# MKL05Z4 register map
Vendor: Freescale Semiconductor, Inc.; Series: Kinetis_L; File version: 1.6
CPU: CM0PLUS r0p0, little endian, no MPU, no FPU, VTOR, 2 interrupt priority bits
Registers are 32-bit, read-write, reset 0x0 unless marked. A register's access mark holds for its fields unless they carry their own. Offsets are from the block's base; [hi:lo] are bit positions; {n}, {i} and the like mark numbered series.

## NVIC — Nested Vectored Interrupt Controller
Base 0xE000E100
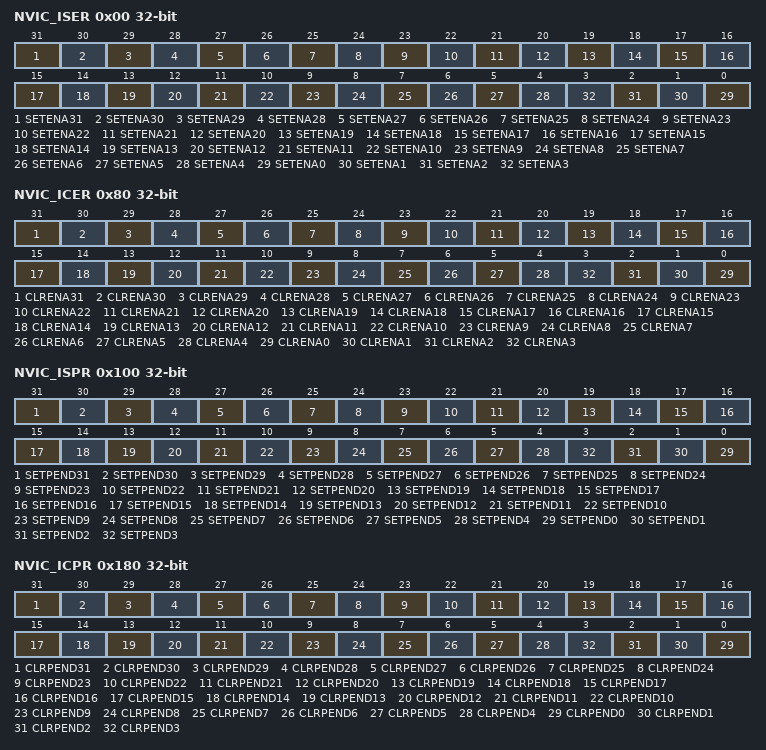
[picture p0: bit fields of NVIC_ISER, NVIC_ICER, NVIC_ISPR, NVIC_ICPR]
0x00 NVIC_ISER — Interrupt Set Enable Register
  [31] SETENA31
    0=write: no effect; read: PORTB Pin detect interrupt disabled; 1=write: enable PORTB Pin detect interrupt; read: PORTB Pin detect interrupt enabled
  [30] SETENA30
    0=write: no effect; read: PORTA Pin detect interrupt disabled; 1=write: enable PORTA Pin detect interrupt; read: PORTA Pin detect interrupt enabled
  [29] SETENA29
    0=write: no effect; read: Reserved iv 45 interrupt disabled; 1=write: enable Reserved iv 45 interrupt; read: Reserved iv 45 interrupt enabled
  [28] SETENA28
    0=write: no effect; read: Low-Power Timer interrupt disabled; 1=write: enable Low-Power Timer interrupt; read: Low-Power Timer interrupt enabled
  [27] SETENA27
    0=write: no effect; read: Multipurpose Clock Generator interrupt disabled; 1=write: enable Multipurpose Clock Generator interrupt; read: Multipurpose Clock Generator interrupt enabled
  [26] SETENA26
    0=write: no effect; read: Touch Sensing Input interrupt disabled; 1=write: enable Touch Sensing Input interrupt; read: Touch Sensing Input interrupt enabled
  [25] SETENA25
    0=write: no effect; read: Digital to Analog Converter interrupt disabled; 1=write: enable Digital to Analog Converter interrupt; read: Digital to Analog Converter interrupt enabled
  [24] SETENA24
    0=write: no effect; read: Reserved iv 40 interrupt disabled; 1=write: enable Reserved iv 40 interrupt; read: Reserved iv 40 interrupt enabled
  [23] SETENA23
    0=write: no effect; read: Reserved iv 39 interrupt disabled; 1=write: enable Reserved iv 39 interrupt; read: Reserved iv 39 interrupt enabled
  [22] SETENA22
    0=write: no effect; read: Periodic Interrupt Timer interrupt disabled; 1=write: enable Periodic Interrupt Timer interrupt; read: Periodic Interrupt Timer interrupt enabled
  [21] SETENA21
    0=write: no effect; read: RTC seconds interrupt disabled; 1=write: enable RTC seconds interrupt; read: RTC seconds interrupt enabled
  [20] SETENA20
    0=write: no effect; read: Real-time counter interrupt disabled; 1=write: enable Real-time counter interrupt; read: Real-time counter interrupt enabled
  [19] SETENA19
    0=write: no effect; read: Reserved iv 35 interrupt disabled; 1=write: enable Reserved iv 35 interrupt; read: Reserved iv 35 interrupt enabled
  [18] SETENA18
    0=write: no effect; read: Timer/PWM module 1 interrupt disabled; 1=write: enable Timer/PWM module 1 interrupt; read: Timer/PWM module 1 interrupt enabled
  [17] SETENA17
    0=write: no effect; read: Timer/PWM module 0 interrupt disabled; 1=write: enable Timer/PWM module 0 interrupt; read: Timer/PWM module 0 interrupt enabled
  [16] SETENA16
    0=write: no effect; read: Comparator 0 interrupt disabled; 1=write: enable Comparator 0 interrupt; read: Comparator 0 interrupt enabled
  [15] SETENA15
    0=write: no effect; read: Analog-to-Digital Converter 0 interrupt disabled; 1=write: enable Analog-to-Digital Converter 0 interrupt; read: Analog-to-Digital Converter 0 interrupt enabled
  [14] SETENA14
    0=write: no effect; read: Reserved iv 30 interrupt disabled; 1=write: enable Reserved iv 30 interrupt; read: Reserved iv 30 interrupt enabled
  [13] SETENA13
    0=write: no effect; read: Reserved iv 29 interrupt disabled; 1=write: enable Reserved iv 29 interrupt; read: Reserved iv 29 interrupt enabled
  [12] SETENA12
    0=write: no effect; read: UART0 status and error interrupt disabled; 1=write: enable UART0 status and error interrupt; read: UART0 status and error interrupt enabled
  [11] SETENA11
    0=write: no effect; read: Reserved iv 27 interrupt disabled; 1=write: enable Reserved iv 27 interrupt; read: Reserved iv 27 interrupt enabled
  [10] SETENA10
    0=write: no effect; read: Serial Peripheral Interface 0 interrupt disabled; 1=write: enable Serial Peripheral Interface 0 interrupt; read: Serial Peripheral Interface 0 interrupt enabled
  [9] SETENA9
    0=write: no effect; read: Reserved iv 25 interrupt disabled; 1=write: enable Reserved iv 25 interrupt; read: Reserved iv 25 interrupt enabled
  [8] SETENA8
    0=write: no effect; read: Inter-Integrated Circuit 0 interrupt disabled; 1=write: enable Inter-Integrated Circuit 0 interrupt; read: Inter-Integrated Circuit 0 interrupt enabled
  [7] SETENA7
    0=write: no effect; read: Low Leakage Wakeup interrupt disabled; 1=write: enable Low Leakage Wakeup interrupt; read: Low Leakage Wakeup interrupt enabled
  [6] SETENA6
    0=write: no effect; read: Low-voltage detect, low-voltage warning interrupt disabled; 1=write: enable Low-voltage detect, low-voltage warning interrupt; read: Low-voltage detect, low-voltage warning interrupt enabled
  [5] SETENA5
    0=write: no effect; read: Command complete and read collision interrupt disabled; 1=write: enable Command complete and read collision interrupt; read: Command complete and read collision interrupt enabled
  [4] SETENA4
    0=write: no effect; read: Reserved iv 20 interrupt disabled; 1=write: enable Reserved iv 20 interrupt; read: Reserved iv 20 interrupt enabled
  [n] SETENA{n} (n=0..3)
    0=write: no effect; read: DMA channel {n} transfer complete interrupt disabled; 1=write: enable DMA channel {n} transfer complete interrupt; read: DMA channel {n} transfer complete interrupt enabled
0x80 NVIC_ICER — Interrupt Clear Enable Register
  [31] CLRENA31
    0=write: no effect; read: PORTB Pin detect interrupt disabled; 1=write: disable PORTB Pin detect interrupt; read: PORTB Pin detect interrupt enabled
  [30] CLRENA30
    0=write: no effect; read: PORTA Pin detect interrupt disabled; 1=write: disable PORTA Pin detect interrupt; read: PORTA Pin detect interrupt enabled
  [29] CLRENA29
    0=write: no effect; read: Reserved iv 45 interrupt disabled; 1=write: disable Reserved iv 45 interrupt; read: Reserved iv 45 interrupt enabled
  [28] CLRENA28
    0=write: no effect; read: Low-Power Timer interrupt disabled; 1=write: disable Low-Power Timer interrupt; read: Low-Power Timer interrupt enabled
  [27] CLRENA27
    0=write: no effect; read: Multipurpose Clock Generator interrupt disabled; 1=write: disable Multipurpose Clock Generator interrupt; read: Multipurpose Clock Generator interrupt enabled
  [26] CLRENA26
    0=write: no effect; read: Touch Sensing Input interrupt disabled; 1=write: disable Touch Sensing Input interrupt; read: Touch Sensing Input interrupt enabled
  [25] CLRENA25
    0=write: no effect; read: Digital to Analog Converter interrupt disabled; 1=write: disable Digital to Analog Converter interrupt; read: Digital to Analog Converter interrupt enabled
  [24] CLRENA24
    0=write: no effect; read: Reserved iv 40 interrupt disabled; 1=write: disable Reserved iv 40 interrupt; read: Reserved iv 40 interrupt enabled
  [23] CLRENA23
    0=write: no effect; read: Reserved iv 39 interrupt disabled; 1=write: disable Reserved iv 39 interrupt; read: Reserved iv 39 interrupt enabled
  [22] CLRENA22
    0=write: no effect; read: Periodic Interrupt Timer interrupt disabled; 1=write: disable Periodic Interrupt Timer interrupt; read: Periodic Interrupt Timer interrupt enabled
  [21] CLRENA21
    0=write: no effect; read: RTC seconds interrupt disabled; 1=write: disable RTC seconds interrupt; read: RTC seconds interrupt enabled
  [20] CLRENA20
    0=write: no effect; read: Real-time counter interrupt disabled; 1=write: disable Real-time counter interrupt; read: Real-time counter interrupt enabled
  [19] CLRENA19
    0=write: no effect; read: Reserved iv 35 interrupt disabled; 1=write: disable Reserved iv 35 interrupt; read: Reserved iv 35 interrupt enabled
  [18] CLRENA18
    0=write: no effect; read: Timer/PWM module 1 interrupt disabled; 1=write: disable Timer/PWM module 1 interrupt; read: Timer/PWM module 1 interrupt enabled
  [17] CLRENA17
    0=write: no effect; read: Timer/PWM module 0 interrupt disabled; 1=write: disable Timer/PWM module 0 interrupt; read: Timer/PWM module 0 interrupt enabled
  [16] CLRENA16
    0=write: no effect; read: Comparator 0 interrupt disabled; 1=write: disable Comparator 0 interrupt; read: Comparator 0 interrupt enabled
  [15] CLRENA15
    0=write: no effect; read: Analog-to-Digital Converter 0 interrupt disabled; 1=write: disable Analog-to-Digital Converter 0 interrupt; read: Analog-to-Digital Converter 0 interrupt enabled
  [14] CLRENA14
    0=write: no effect; read: Reserved iv 30 interrupt disabled; 1=write: disable Reserved iv 30 interrupt; read: Reserved iv 30 interrupt enabled
  [13] CLRENA13
    0=write: no effect; read: Reserved iv 29 interrupt disabled; 1=write: disable Reserved iv 29 interrupt; read: Reserved iv 29 interrupt enabled
  [12] CLRENA12
    0=write: no effect; read: UART0 status and error interrupt disabled; 1=write: disable UART0 status and error interrupt; read: UART0 status and error interrupt enabled
  [11] CLRENA11
    0=write: no effect; read: Reserved iv 27 interrupt disabled; 1=write: disable Reserved iv 27 interrupt; read: Reserved iv 27 interrupt enabled
  [10] CLRENA10
    0=write: no effect; read: Serial Peripheral Interface 0 interrupt disabled; 1=write: disable Serial Peripheral Interface 0 interrupt; read: Serial Peripheral Interface 0 interrupt enabled
  [9] CLRENA9
    0=write: no effect; read: Reserved iv 25 interrupt disabled; 1=write: disable Reserved iv 25 interrupt; read: Reserved iv 25 interrupt enabled
  [8] CLRENA8
    0=write: no effect; read: Inter-Integrated Circuit 0 interrupt disabled; 1=write: disable Inter-Integrated Circuit 0 interrupt; read: Inter-Integrated Circuit 0 interrupt enabled
  [7] CLRENA7
    0=write: no effect; read: Low Leakage Wakeup interrupt disabled; 1=write: disable Low Leakage Wakeup interrupt; read: Low Leakage Wakeup interrupt enabled
  [6] CLRENA6
    0=write: no effect; read: Low-voltage detect, low-voltage warning interrupt disabled; 1=write: disable Low-voltage detect, low-voltage warning interrupt; read: Low-voltage detect, low-voltage warning interrupt enabled
  [5] CLRENA5
    0=write: no effect; read: Command complete and read collision interrupt disabled; 1=write: disable Command complete and read collision interrupt; read: Command complete and read collision interrupt enabled
  [4] CLRENA4
    0=write: no effect; read: Reserved iv 20 interrupt disabled; 1=write: disable Reserved iv 20 interrupt; read: Reserved iv 20 interrupt enabled
  [n] CLRENA{n} (n=0..3)
    0=write: no effect; read: DMA channel {n} transfer complete interrupt disabled; 1=write: disable DMA channel {n} transfer complete interrupt; read: DMA channel {n} transfer complete interrupt enabled
0x100 NVIC_ISPR — Interrupt Set Pending Register
  [31] SETPEND31
    0=write: no effect; read: PORTB Pin detect interrupt is not pending; 1=write: changes the PORTB Pin detect interrupt state to pending; read: PORTB Pin detect interrupt is pending
  [30] SETPEND30
    0=write: no effect; read: PORTA Pin detect interrupt is not pending; 1=write: changes the PORTA Pin detect interrupt state to pending; read: PORTA Pin detect interrupt is pending
  [29] SETPEND29
    0=write: no effect; read: Reserved iv 45 interrupt is not pending; 1=write: changes the Reserved iv 45 interrupt state to pending; read: Reserved iv 45 interrupt is pending
  [28] SETPEND28
    0=write: no effect; read: Low-Power Timer interrupt is not pending; 1=write: changes the Low-Power Timer interrupt state to pending; read: Low-Power Timer interrupt is pending
  [27] SETPEND27
    0=write: no effect; read: Multipurpose Clock Generator interrupt is not pending; 1=write: changes the Multipurpose Clock Generator interrupt state to pending; read: Multipurpose Clock Generator interrupt is pending
  [26] SETPEND26
    0=write: no effect; read: Touch Sensing Input interrupt is not pending; 1=write: changes the Touch Sensing Input interrupt state to pending; read: Touch Sensing Input interrupt is pending
  [25] SETPEND25
    0=write: no effect; read: Digital to Analog Converter interrupt is not pending; 1=write: changes the Digital to Analog Converter interrupt state to pending; read: Digital to Analog Converter interrupt is pending
  [24] SETPEND24
    0=write: no effect; read: Reserved iv 40 interrupt is not pending; 1=write: changes the Reserved iv 40 interrupt state to pending; read: Reserved iv 40 interrupt is pending
  [23] SETPEND23
    0=write: no effect; read: Reserved iv 39 interrupt is not pending; 1=write: changes the Reserved iv 39 interrupt state to pending; read: Reserved iv 39 interrupt is pending
  [22] SETPEND22
    0=write: no effect; read: Periodic Interrupt Timer interrupt is not pending; 1=write: changes the Periodic Interrupt Timer interrupt state to pending; read: Periodic Interrupt Timer interrupt is pending
  [21] SETPEND21
    0=write: no effect; read: RTC seconds interrupt is not pending; 1=write: changes the RTC seconds interrupt state to pending; read: RTC seconds interrupt is pending
  [20] SETPEND20
    0=write: no effect; read: Real-time counter interrupt is not pending; 1=write: changes the Real-time counter interrupt state to pending; read: Real-time counter interrupt is pending
  [19] SETPEND19
    0=write: no effect; read: Reserved iv 35 interrupt is not pending; 1=write: changes the Reserved iv 35 interrupt state to pending; read: Reserved iv 35 interrupt is pending
  [18] SETPEND18
    0=write: no effect; read: Timer/PWM module 1 interrupt is not pending; 1=write: changes the Timer/PWM module 1 interrupt state to pending; read: Timer/PWM module 1 interrupt is pending
  [17] SETPEND17
    0=write: no effect; read: Timer/PWM module 0 interrupt is not pending; 1=write: changes the Timer/PWM module 0 interrupt state to pending; read: Timer/PWM module 0 interrupt is pending
  [16] SETPEND16
    0=write: no effect; read: Comparator 0 interrupt is not pending; 1=write: changes the Comparator 0 interrupt state to pending; read: Comparator 0 interrupt is pending
  [15] SETPEND15
    0=write: no effect; read: Analog-to-Digital Converter 0 interrupt is not pending; 1=write: changes the Analog-to-Digital Converter 0 interrupt state to pending; read: Analog-to-Digital Converter 0 interrupt is pending
  [14] SETPEND14
    0=write: no effect; read: Reserved iv 30 interrupt is not pending; 1=write: changes the Reserved iv 30 interrupt state to pending; read: Reserved iv 30 interrupt is pending
  [13] SETPEND13
    0=write: no effect; read: Reserved iv 29 interrupt is not pending; 1=write: changes the Reserved iv 29 interrupt state to pending; read: Reserved iv 29 interrupt is pending
  [12] SETPEND12
    0=write: no effect; read: UART0 status and error interrupt is not pending; 1=write: changes the UART0 status and error interrupt state to pending; read: UART0 status and error interrupt is pending
  [11] SETPEND11
    0=write: no effect; read: Reserved iv 27 interrupt is not pending; 1=write: changes the Reserved iv 27 interrupt state to pending; read: Reserved iv 27 interrupt is pending
  [10] SETPEND10
    0=write: no effect; read: Serial Peripheral Interface 0 interrupt is not pending; 1=write: changes the Serial Peripheral Interface 0 interrupt state to pending; read: Serial Peripheral Interface 0 interrupt is pending
  [9] SETPEND9
    0=write: no effect; read: Reserved iv 25 interrupt is not pending; 1=write: changes the Reserved iv 25 interrupt state to pending; read: Reserved iv 25 interrupt is pending
  [8] SETPEND8
    0=write: no effect; read: Inter-Integrated Circuit 0 interrupt is not pending; 1=write: changes the Inter-Integrated Circuit 0 interrupt state to pending; read: Inter-Integrated Circuit 0 interrupt is pending
  [7] SETPEND7
    0=write: no effect; read: Low Leakage Wakeup interrupt is not pending; 1=write: changes the Low Leakage Wakeup interrupt state to pending; read: Low Leakage Wakeup interrupt is pending
  [6] SETPEND6
    0=write: no effect; read: Low-voltage detect, low-voltage warning interrupt is not pending; 1=write: changes the Low-voltage detect, low-voltage warning interrupt state to pending; read: Low-voltage detect, low-voltage warning interrupt is pending
  [5] SETPEND5
    0=write: no effect; read: Command complete and read collision interrupt is not pending; 1=write: changes the Command complete and read collision interrupt state to pending; read: Command complete and read collision interrupt is pending
  [4] SETPEND4
    0=write: no effect; read: Reserved iv 20 interrupt is not pending; 1=write: changes the Reserved iv 20 interrupt state to pending; read: Reserved iv 20 interrupt is pending
  [n] SETPEND{n} (n=0..3)
    0=write: no effect; read: DMA channel {n} transfer complete interrupt is not pending; 1=write: changes the DMA channel {n} transfer complete interrupt state to pending; read: DMA channel {n} transfer complete interrupt is pending
0x180 NVIC_ICPR — Interrupt Clear Pending Register
  [31] CLRPEND31
    0=write: no effect; read: PORTB Pin detect interrupt is not pending; 1=write: removes pending state from the PORTB Pin detect interrupt; read: PORTB Pin detect interrupt is pending
  [30] CLRPEND30
    0=write: no effect; read: PORTA Pin detect interrupt is not pending; 1=write: removes pending state from the PORTA Pin detect interrupt; read: PORTA Pin detect interrupt is pending
  [29] CLRPEND29
    0=write: no effect; read: Reserved iv 45 interrupt is not pending; 1=write: removes pending state from the Reserved iv 45 interrupt; read: Reserved iv 45 interrupt is pending
  [28] CLRPEND28
    0=write: no effect; read: Low-Power Timer interrupt is not pending; 1=write: removes pending state from the Low-Power Timer interrupt; read: Low-Power Timer interrupt is pending
  [27] CLRPEND27
    0=write: no effect; read: Multipurpose Clock Generator interrupt is not pending; 1=write: removes pending state from the Multipurpose Clock Generator interrupt; read: Multipurpose Clock Generator interrupt is pending
  [26] CLRPEND26
    0=write: no effect; read: Touch Sensing Input interrupt is not pending; 1=write: removes pending state from the Touch Sensing Input interrupt; read: Touch Sensing Input interrupt is pending
  [25] CLRPEND25
    0=write: no effect; read: Digital to Analog Converter interrupt is not pending; 1=write: removes pending state from the Digital to Analog Converter interrupt; read: Digital to Analog Converter interrupt is pending
  [24] CLRPEND24
    0=write: no effect; read: Reserved iv 40 interrupt is not pending; 1=write: removes pending state from the Reserved iv 40 interrupt; read: Reserved iv 40 interrupt is pending
  [23] CLRPEND23
    0=write: no effect; read: Reserved iv 39 interrupt is not pending; 1=write: removes pending state from the Reserved iv 39 interrupt; read: Reserved iv 39 interrupt is pending
  [22] CLRPEND22
    0=write: no effect; read: Periodic Interrupt Timer interrupt is not pending; 1=write: removes pending state from the Periodic Interrupt Timer interrupt; read: Periodic Interrupt Timer interrupt is pending
  [21] CLRPEND21
    0=write: no effect; read: RTC seconds interrupt is not pending; 1=write: removes pending state from the RTC seconds interrupt; read: RTC seconds interrupt is pending
  [20] CLRPEND20
    0=write: no effect; read: Real-time counter interrupt is not pending; 1=write: removes pending state from the Real-time counter interrupt; read: Real-time counter interrupt is pending
  [19] CLRPEND19
    0=write: no effect; read: Reserved iv 35 interrupt is not pending; 1=write: removes pending state from the Reserved iv 35 interrupt; read: Reserved iv 35 interrupt is pending
  [18] CLRPEND18
    0=write: no effect; read: Timer/PWM module 1 interrupt is not pending; 1=write: removes pending state from the Timer/PWM module 1 interrupt; read: Timer/PWM module 1 interrupt is pending
  [17] CLRPEND17
    0=write: no effect; read: Timer/PWM module 0 interrupt is not pending; 1=write: removes pending state from the Timer/PWM module 0 interrupt; read: Timer/PWM module 0 interrupt is pending
  [16] CLRPEND16
    0=write: no effect; read: Comparator 0 interrupt is not pending; 1=write: removes pending state from the Comparator 0 interrupt; read: Comparator 0 interrupt is pending
  [15] CLRPEND15
    0=write: no effect; read: Analog-to-Digital Converter 0 interrupt is not pending; 1=write: removes pending state from the Analog-to-Digital Converter 0 interrupt; read: Analog-to-Digital Converter 0 interrupt is pending
  [14] CLRPEND14
    0=write: no effect; read: Reserved iv 30 interrupt is not pending; 1=write: removes pending state from the Reserved iv 30 interrupt; read: Reserved iv 30 interrupt is pending
  [13] CLRPEND13
    0=write: no effect; read: Reserved iv 29 interrupt is not pending; 1=write: removes pending state from the Reserved iv 29 interrupt; read: Reserved iv 29 interrupt is pending
  [12] CLRPEND12
    0=write: no effect; read: UART0 status and error interrupt is not pending; 1=write: removes pending state from the UART0 status and error interrupt; read: UART0 status and error interrupt is pending
  [11] CLRPEND11
    0=write: no effect; read: Reserved iv 27 interrupt is not pending; 1=write: removes pending state from the Reserved iv 27 interrupt; read: Reserved iv 27 interrupt is pending
  [10] CLRPEND10
    0=write: no effect; read: Serial Peripheral Interface 0 interrupt is not pending; 1=write: removes pending state from the Serial Peripheral Interface 0 interrupt; read: Serial Peripheral Interface 0 interrupt is pending
  [9] CLRPEND9
    0=write: no effect; read: Reserved iv 25 interrupt is not pending; 1=write: removes pending state from the Reserved iv 25 interrupt; read: Reserved iv 25 interrupt is pending
  [8] CLRPEND8
    0=write: no effect; read: Inter-Integrated Circuit 0 interrupt is not pending; 1=write: removes pending state from the Inter-Integrated Circuit 0 interrupt; read: Inter-Integrated Circuit 0 interrupt is pending
  [7] CLRPEND7
    0=write: no effect; read: Low Leakage Wakeup interrupt is not pending; 1=write: removes pending state from the Low Leakage Wakeup interrupt; read: Low Leakage Wakeup interrupt is pending
  [6] CLRPEND6
    0=write: no effect; read: Low-voltage detect, low-voltage warning interrupt is not pending; 1=write: removes pending state from the Low-voltage detect, low-voltage warning interrupt; read: Low-voltage detect, low-voltage warning interrupt is pending
  [5] CLRPEND5
    0=write: no effect; read: Command complete and read collision interrupt is not pending; 1=write: removes pending state from the Command complete and read collision interrupt; read: Command complete and read collision interrupt is pending
  [4] CLRPEND4
    0=write: no effect; read: Reserved iv 20 interrupt is not pending; 1=write: removes pending state from the Reserved iv 20 interrupt; read: Reserved iv 20 interrupt is pending
  [n] CLRPEND{n} (n=0..3)
    0=write: no effect; read: DMA channel {n} transfer complete interrupt is not pending; 1=write: removes pending state from the DMA channel {n} transfer complete interrupt; read: DMA channel {n} transfer complete interrupt is pending
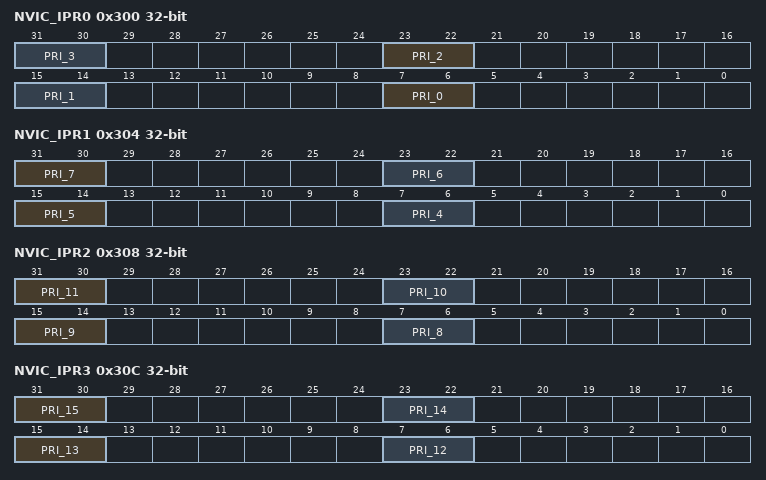
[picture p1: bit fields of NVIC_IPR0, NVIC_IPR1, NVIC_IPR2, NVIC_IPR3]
0x300 NVIC_IPR0 — Interrupt Priority Register 0
  [8n+7:8n+6] PRI_{n} (n=0..3) — Priority of the DMA channel {n} transfer complete interrupt
0x304 NVIC_IPR1 — Interrupt Priority Register 1
  [31:30] PRI_7 — Priority of the Low Leakage Wakeup interrupt
  [23:22] PRI_6 — Priority of the Low-voltage detect, low-voltage warning interrupt
  [15:14] PRI_5 — Priority of the Command complete and read collision interrupt
  [7:6] PRI_4 — Priority of the Reserved iv 20 interrupt
0x308 NVIC_IPR2 — Interrupt Priority Register 2
  [31:30] PRI_11 — Priority of the Reserved iv 27 interrupt
  [23:22] PRI_10 — Priority of the Serial Peripheral Interface 0 interrupt
  [15:14] PRI_9 — Priority of the Reserved iv 25 interrupt
  [7:6] PRI_8 — Priority of the Inter-Integrated Circuit 0 interrupt
0x30C NVIC_IPR3 — Interrupt Priority Register 3
  [31:30] PRI_15 — Priority of the Analog-to-Digital Converter 0 interrupt
  [23:22] PRI_14 — Priority of the Reserved iv 30 interrupt
  [15:14] PRI_13 — Priority of the Reserved iv 29 interrupt
  [7:6] PRI_12 — Priority of the UART0 status and error interrupt
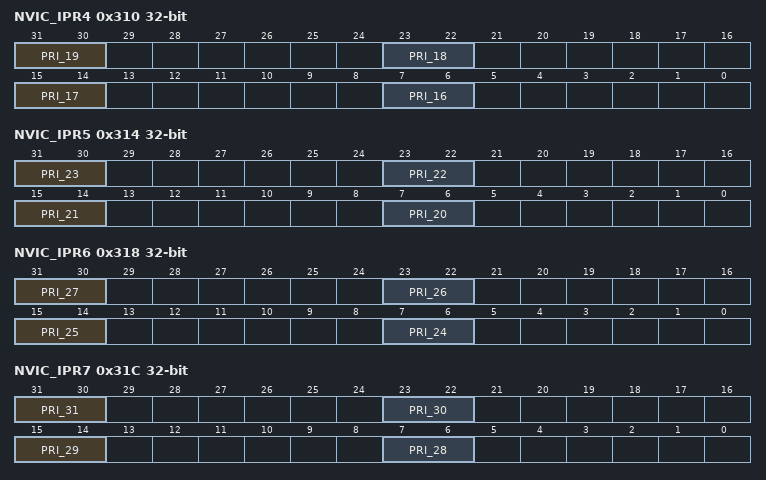
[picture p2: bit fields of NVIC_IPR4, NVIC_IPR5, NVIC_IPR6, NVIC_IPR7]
0x310 NVIC_IPR4 — Interrupt Priority Register 4
  [31:30] PRI_19 — Priority of the Reserved iv 35 interrupt
  [23:22] PRI_18 — Priority of the Timer/PWM module 1 interrupt
  [15:14] PRI_17 — Priority of the Timer/PWM module 0 interrupt
  [7:6] PRI_16 — Priority of the Comparator 0 interrupt
0x314 NVIC_IPR5 — Interrupt Priority Register 5
  [31:30] PRI_23 — Priority of the Reserved iv 39 interrupt
  [23:22] PRI_22 — Priority of the Periodic Interrupt Timer interrupt
  [15:14] PRI_21 — Priority of the RTC seconds interrupt
  [7:6] PRI_20 — Priority of the Real-time counter interrupt
0x318 NVIC_IPR6 — Interrupt Priority Register 6
  [31:30] PRI_27 — Priority of the Multipurpose Clock Generator interrupt
  [23:22] PRI_26 — Priority of the Touch Sensing Input interrupt
  [15:14] PRI_25 — Priority of the Digital to Analog Converter interrupt
  [7:6] PRI_24 — Priority of the Reserved iv 40 interrupt
0x31C NVIC_IPR7 — Interrupt Priority Register 7
  [31:30] PRI_31 — Priority of the PORTB Pin detect interrupt
  [23:22] PRI_30 — Priority of the PORTA Pin detect interrupt
  [15:14] PRI_29 — Priority of the Reserved iv 45 interrupt
  [7:6] PRI_28 — Priority of the Low-Power Timer interrupt
